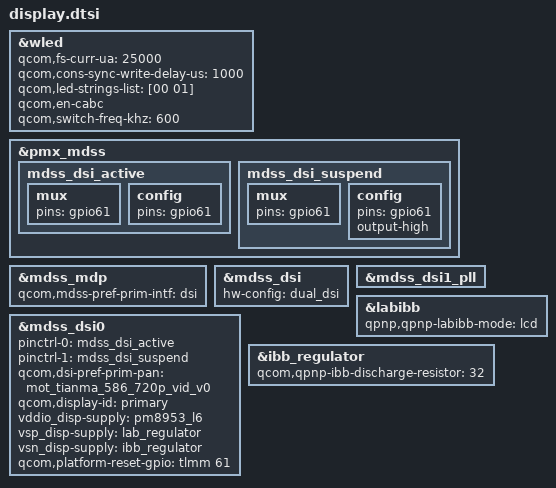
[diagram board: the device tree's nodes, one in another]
/* Copyright (c) 2018, Motorola Mobility Inc. All rights reserved.
 *
 * This program is free software; you can redistribute it and/or modify
 * it under the terms of the GNU General Public License version 2 and
 * only version 2 as published by the Free Software Foundation.
 *
 * This program is distributed in the hope that it will be useful,
 * but WITHOUT ANY WARRANTY; without even the implied warranty of
 * MERCHANTABILITY or FITNESS FOR A PARTICULAR PURPOSE.  See the
 * GNU General Public License for more details.
 */

#include "dsi-panel/dsi-panel-mot-tianma-586-720p-vid.dtsi"
#include "dsi-panel/dsi-panel-mot-nova-586-hd-vid.dtsi"

&wled {
	qcom,fs-curr-ua = <25000>;
	qcom,cons-sync-write-delay-us = <1000>;
	qcom,led-strings-list = [00 01];
	qcom,en-cabc;
	qcom,switch-freq-khz = <600>;
};

&pmx_mdss {
	mdss_dsi_active {
		mux {
			pins = "gpio61";
		};

		config {
			/delete-property/ output-high;
			pins = "gpio61";
		};
	};

	mdss_dsi_suspend {
		mux {
			pins = "gpio61";
		};

		config {
			pins = "gpio61";
			output-high;
		};
	};
};

&mdss_mdp {
	qcom,mdss-pref-prim-intf = "dsi";
};

&mdss_dsi {
	hw-config = "dual_dsi";
};


&mdss_dsi0 {
	pinctrl-names = "mdss_default", "mdss_sleep";
	pinctrl-0 = <&mdss_dsi_active>;
	pinctrl-1 = <&mdss_dsi_suspend>;

	qcom,dsi-pref-prim-pan = <&mot_tianma_586_720p_vid_v0>;
	qcom,display-id = "primary";

	/delete-property/ vdd-supply;
	vddio_disp-supply = <&pm8953_l6>;
	vsp_disp-supply = <&lab_regulator>;
	vsn_disp-supply = <&ibb_regulator>;

	qcom,platform-reset-gpio = <&tlmm 61 0>;
};

&mdss_dsi1_pll {
	/delete-property/ qcom,dsi-pll-ssc-en;
	/delete-property/ qcom,dsi-pll-ssc-mode;
};

/* display boost and inverting boost regulators */
&labibb {
	status = "ok";
	qpnp,qpnp-labibb-mode = "lcd";
};

&ibb_regulator {
	qcom,qpnp-ibb-discharge-resistor = <32>;
};

